# M3HN register map
File version: 0.1
Registers are 32-bit, read-write, reset 0x0 unless marked. A register's access mark holds for its fields unless they carry their own. Offsets are from the block's base; [hi:lo] are bit positions; {n}, {i} and the like mark numbered series.

## OFD
Base 0x400F1000
0x00 CR1 reset 0x6 — OFD Control Register 1
  [7:0] OFDWEN
0x04 CR2 — OFD Control Register 2
  [7:0] OFDEN
0x08 MN0 — OFD Lower Detection Frequency Setting Register0
  [11:0] OFDMN0
0x0C MN1 — OFD Lower Detection Frequency Setting Register1
  [11:0] OFDMN1
0x10 MX0 — OFD Higher Detection Frequency Setting Register0
  [11:0] OFDMX0
0x14 MX1 — OFD Higher Detection Frequency Setting Register1
  [11:0] OFDMX1
0x18 RST reset 0x1 — OFD Reset Enable Control Register
  [0] OFDRSTEN
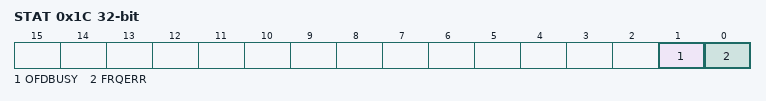
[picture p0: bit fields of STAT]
0x1C STAT ro — OFD Status Register
  [1] OFDBUSY, [0] FRQERR
0x20 MON reset 0x1 — OFD External high frequency oscillaion clock monitor register
  [0] OFDMON

## CG
Base 0x400F3000
0x00 PROTECT reset 0xC1 — CG Protect Register
  [7:0] PROTECT
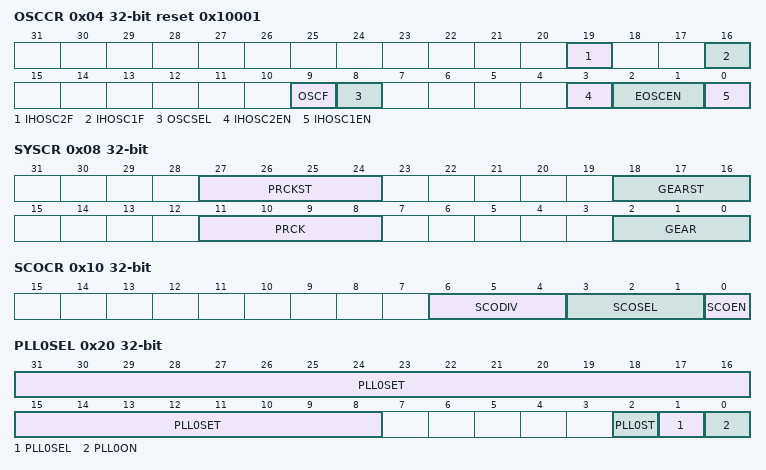
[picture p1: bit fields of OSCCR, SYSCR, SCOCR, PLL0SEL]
0x04 OSCCR reset 0x10001 — CG Oscillation Control Register
  [19] IHOSC2F ro, [16] IHOSC1F ro, [9] OSCF ro, [8] OSCSEL, [3] IHOSC2EN, [2:1] EOSCEN, [0] IHOSC1EN
0x08 SYSCR — CG System clock control register
  [27:24] PRCKST ro, [18:16] GEARST ro, [11:8] PRCK, [2:0] GEAR
0x0C STBYCR — CG Standby Control Register
  [1:0] STBY
0x10 SCOCR — CG SCOUT Control Register
  [6:4] SCODIV, [3:1] SCOSEL, [0] SCOEN
0x20 PLL0SEL — CG PLL select register for fsys
  [31:8] PLL0SET, [2] PLL0ST ro, [1] PLL0SEL, [0] PLL0ON
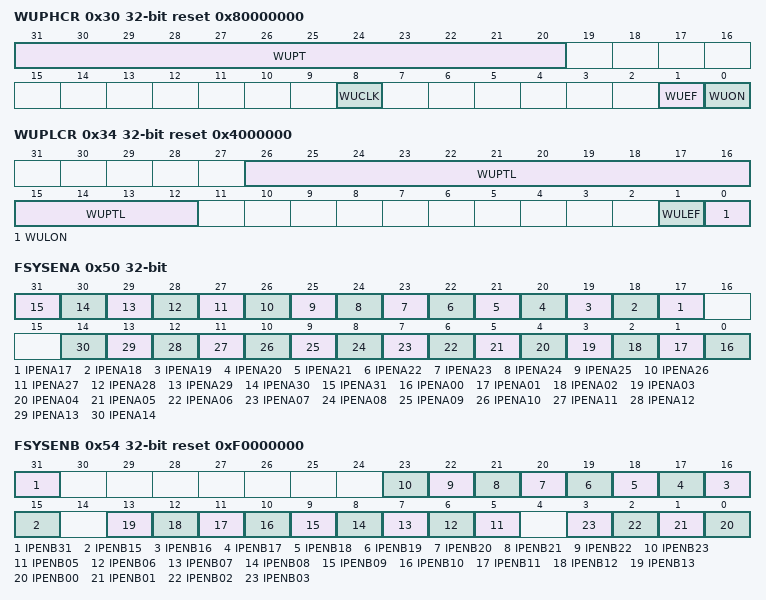
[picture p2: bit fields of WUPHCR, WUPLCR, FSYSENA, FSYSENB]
0x30 WUPHCR reset 0x80000000 — CG Warmup register for HOSC
  [31:20] WUPT, [8] WUCLK, [1] WUEF ro, [0] WUON wo
0x34 WUPLCR reset 0x4000000 — CG Low-speed oscillation warm-up register
  [26:12] WUPTL, [1] WULEF ro, [0] WULON wo
0x50 FSYSENA — CG output control register A for fsys clock
  [n] IPENA{n} (n=17..31), [n] IPENA{n:02} (n=0..14)
0x54 FSYSENB reset 0xF0000000 — CG output control register B for fsys clock
  [31] IPENB31, [n] IPENB{n} (n=15..23), [n] IPENB{n:02} (n=5..13), [n] IPENB{n:02} (n=0..3)
0x58 FCEN — CG output control register for fc clock
  [7] FCIPEN07
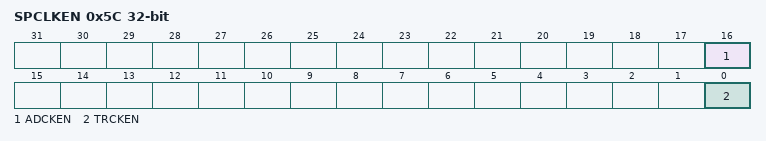
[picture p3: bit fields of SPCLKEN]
0x5C SPCLKEN — CG Output control register for ADC AND TRACE CLOCK
  [16] ADCKEN, [0] TRCKEN

## TRM
Base 0x400F3200
0x00 OSCPRO — TRM Protect register
  [7:0] PROTECT
0x04 OSCEN — TRM Enable register
  [0] TRIMEN
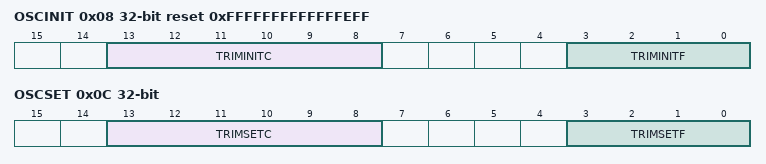
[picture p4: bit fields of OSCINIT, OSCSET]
0x08 OSCINIT ro reset 0xFFFFFFFFFFFFFEFF — TRM Initial trimming level monitor register
  [13:8] TRIMINITC, [3:0] TRIMINITF
0x0C OSCSET — TRM Trimming level setting register
  [13:8] TRIMSETC, [3:0] TRIMSETF

## IB — Interrupt control register B
Base 0x400F4E00
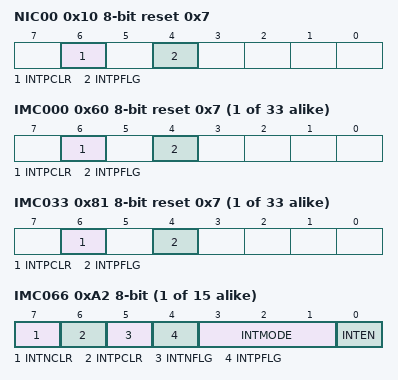
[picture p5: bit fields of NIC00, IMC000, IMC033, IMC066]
0x10 NIC00 8-bit reset 0x7 — Non makeable Interrupt Control(B) 00
  [6] INTPCLR wo, [4] INTPFLG ro
{0x60+i} IMC{i:03} 8-bit reset 0x7 (i=0..32) — Interrupu Mode Control Register(B) {i:03}
  [6] INTPCLR wo, [4] INTPFLG ro
{0x60+i} IMC{i:03} 8-bit reset 0x7 (i=33..65) — Interrupt Mode Control Register(B) {i:03}
  [6] INTPCLR wo, [4] INTPFLG ro
{0x60+i} IMC{i:03} 8-bit (i=66..80) — Interrupu Mode Control Register(B) {i:03}
  [7] INTNCLR wo, [6] INTPCLR wo, [5] INTNFLG ro, [4] INTPFLG ro, [3:1] INTMODE, [0] INTEN
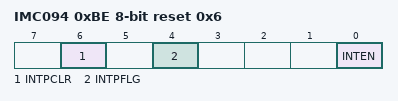
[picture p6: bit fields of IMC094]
0xBE IMC094 8-bit reset 0x6 — Interrupu Mode Control Register(B) 094
  [6] INTPCLR wo, [4] INTPFLG ro, [0] INTEN

## IMN
Base 0x400F4F00
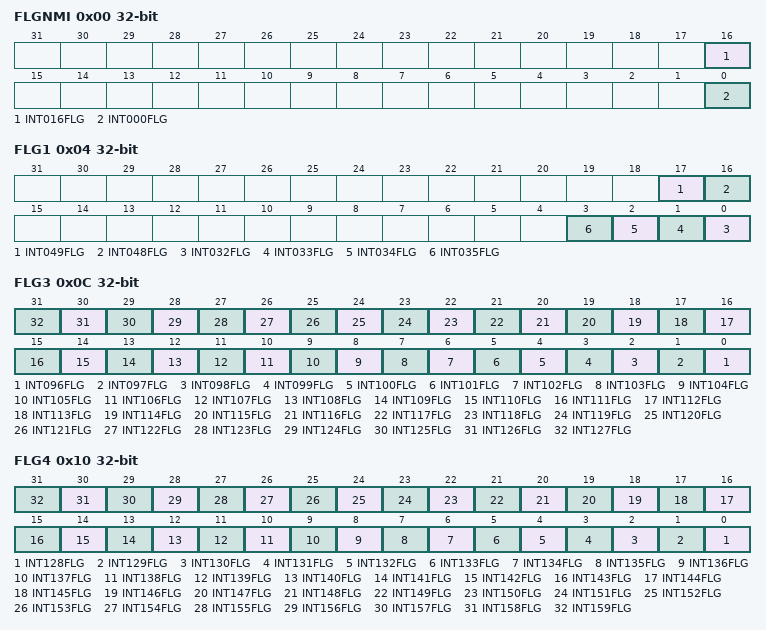
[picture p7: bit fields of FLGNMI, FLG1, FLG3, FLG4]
0x00 FLGNMI ro — Interrupt Monitor Flag 0
  [16] INT016FLG, [0] INT000FLG
0x04 FLG1 ro — Interrupt Monitor Flag 1
  [17] INT049FLG, [16] INT048FLG, [n-32] INT{n:03}FLG (n=32..35)
0x0C FLG3 ro — Interrupt Monitor Flag 3
  [n-96] INT{n:03}FLG (n=96..127)
0x10 FLG4 ro — NMI Interrupt Monitor Flag 4
  [n-128] INT{n}FLG (n=128..159)
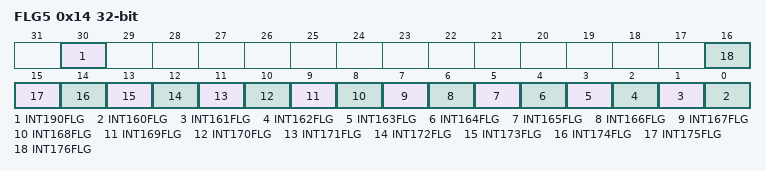
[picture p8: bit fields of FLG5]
0x14 FLG5 ro — NMI Interrupt Monitor Flag 5
  [30] INT190FLG, [n-160] INT{n}FLG (n=160..176)

## PMD
Base 0x400F6000
0x00 MDEN — PMD Enable Register
  [0] PWMEN
0x04 PORTMD — PMD Port Output Mode Register
  [1:0] PORTMD
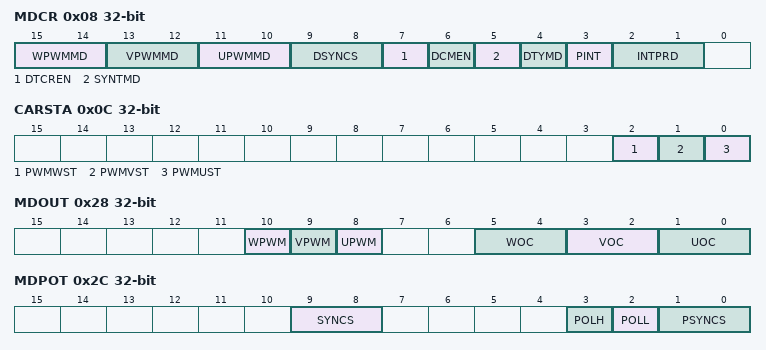
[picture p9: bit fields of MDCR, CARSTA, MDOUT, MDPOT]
0x08 MDCR — PMD Control Register
  [15:14] WPWMMD, [13:12] VPWMMD, [11:10] UPWMMD, [9:8] DSYNCS, [7] DTCREN, [6] DCMEN, [5] SYNTMD, [4] DTYMD, [3] PINT, [2:1] INTPRD
0x0C CARSTA ro — PWM Carrier Status Register
  [2] PWMWST, [1] PWMVST, [0] PWMUST
0x10 BCARI ro — PWM Basic Carrier Register
  [14:0] BCARI
0x14 RATE — PWM Frequency Register
  [14:0] RATE
0x18 CMPU — PMD PWM Compare U Register
  [15:0] CMPU
0x1C CMPV — PMD PWM Compare V Register
  [15:0] CMPV
0x20 CMPW — PMD PWM Compare W Register
  [15:0] CMPW
0x28 MDOUT — PMD Conduction Control Register
  [10] WPWM, [9] VPWM, [8] UPWM, [5:4] WOC, [3:2] VOC, [1:0] UOC
0x2C MDPOT — PMD Output Setting Register
  [9:8] SYNCS, [3] POLH, [2] POLL, [1:0] PSYNCS
0x30 EMGREL wo — PMD EMG Release Register
  [7:0] EMGREL
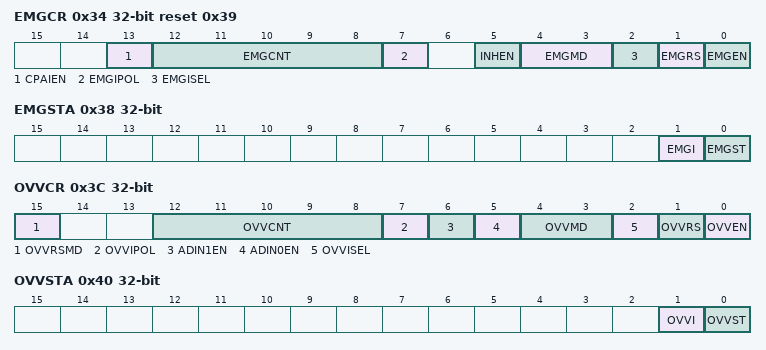
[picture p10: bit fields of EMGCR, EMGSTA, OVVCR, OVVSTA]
0x34 EMGCR reset 0x39 — PMD EMG Control Register
  [13] CPAIEN, [12:8] EMGCNT, [7] EMGIPOL, [5] INHEN, [4:3] EMGMD, [2] EMGISEL, [1] EMGRS wo, [0] EMGEN
0x38 EMGSTA ro (reset mask 0xFFFFFFFD) — PMD EMG Status Register
  [1] EMGI, [0] EMGST
0x3C OVVCR — PMD OVV Control Register
  [15] OVVRSMD, [12:8] OVVCNT, [7] OVVIPOL, [6] ADIN1EN, [5] ADIN0EN, [4:3] OVVMD, [2] OVVISEL, [1] OVVRS wo, [0] OVVEN
0x40 OVVSTA ro (reset mask 0xFFFFFFFD) — PMD OVV Status Register
  [1] OVVI, [0] OVVST
0x44 DTR — PMD Dead Time Register
  [9:0] DTR
{0x48+4i} TRGCMP{i} (i=0..3) — PMD Trigger Compare Register {i}
  [14:0] TRGCMP{i}
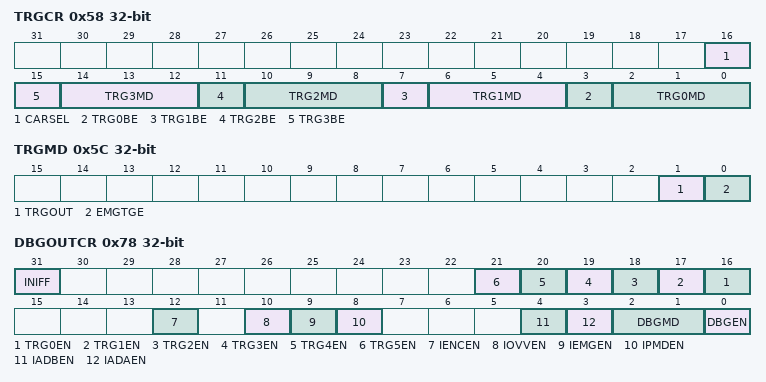
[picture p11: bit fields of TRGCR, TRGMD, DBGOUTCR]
0x58 TRGCR — PMD Trigger Control Register
  [16] CARSEL, [4n+3] TRG{n}BE (n=0..3), [4n+2:4n] TRG{n}MD (n=0..3)
0x5C TRGMD — PMD Trigger Output Mode Setting Register
  [1] TRGOUT, [0] EMGTGE
0x60 TRGSEL — PMD Trigger Output Select Register
  [2:0] TRGSEL
0x64 TRGSYNCR — PMD Trigger Update Timing Setting Register
  [1:0] TSYNCS
0x68 VPWMPH — Phase difference setting of the V-phase PWM
  [14:0] VPWMPH
0x6C WPWMPH — Phase difference setting of the W-phase PWM
  [14:0] WPWMPH
0x70 MBUFCR — Update timing of the triple buffer
  [2:0] BUFCTR
0x78 DBGOUTCR — Debug output control
  [31] INIFF, [n+16] TRG{n}EN (n=0..5), [12] IENCEN, [10] IOVVEN, [9] IEMGEN, [8] IPMDEN, [4] IADBEN, [3] IADAEN, [2:1] DBGMD, [0] DBGEN

## EN — Encoder Input (ENC)
Base 0x400F7000
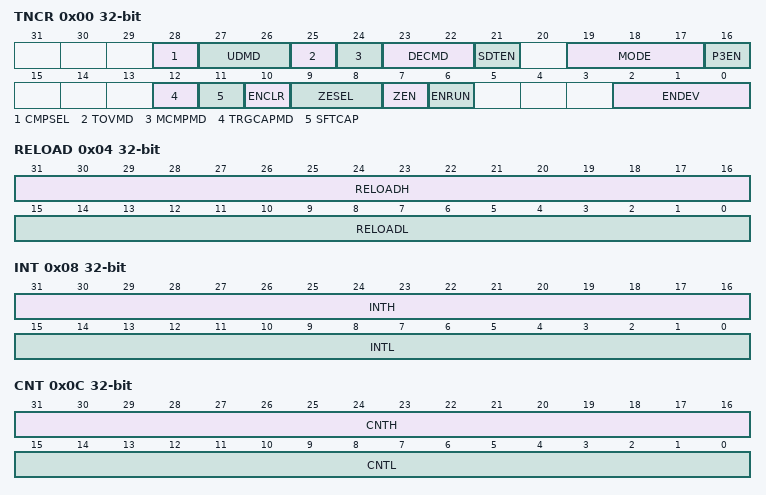
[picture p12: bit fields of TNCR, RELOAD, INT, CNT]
0x00 TNCR — ENC Control Register
  [28] CMPSEL, [27:26] UDMD, [25] TOVMD, [24] MCMPMD, [23:22] DECMD, [21] SDTEN, [19:17] MODE, [16] P3EN, [12] TRGCAPMD, [11] SFTCAP wo, [10] ENCLR wo, [9:8] ZESEL, [7] ZEN, [6] ENRUN, [2:0] ENDEV
0x04 RELOAD — ENC Reload Compare Register
  [31:16] RELOADH, [15:0] RELOADL
0x08 INT — ENC INT Compare Register
  [31:16] INTH, [15:0] INTL
0x0C CNT — ENC Counter_Capture Register
  [31:16] CNTH ro, [15:0] CNTL ro
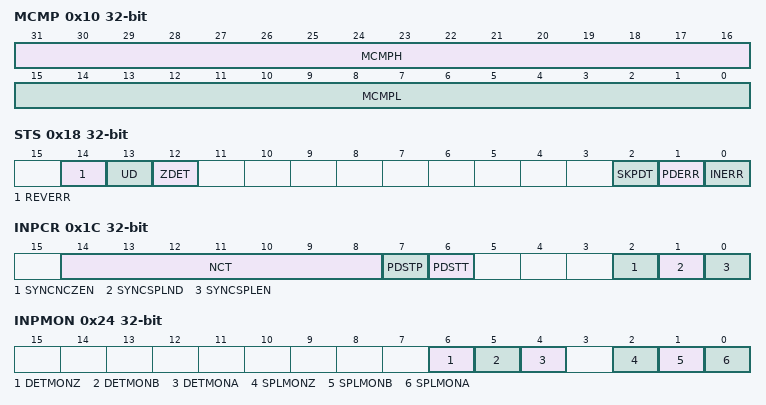
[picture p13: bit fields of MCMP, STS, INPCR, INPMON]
0x10 MCMP — ENC MCMP Compare Register
  [31:16] MCMPH, [15:0] MCMPL
0x14 RATE — ENC Phase Count Rate Register
  [15:0] RATE
0x18 STS ro — ENC Status Register
  [14] REVERR, [13] UD, [12] ZDET, [2] SKPDT, [1] PDERR, [0] INERR
0x1C INPCR — ENC Input Process Cntrol Register
  [14:8] NCT, [7] PDSTP wo, [6] PDSTT wo, [2] SYNCNCZEN, [1] SYNCSPLND, [0] SYNCSPLEN
0x20 SMPDLY — ENC Sample Delay Register
  [7:0] SMPDLY
0x24 INPMON ro — ENC Input Moniter Register
  [6] DETMONZ, [5] DETMONB, [4] DETMONA, [2] SPLMONZ, [1] SPLMONB, [0] SPLMONA
0x28 CLKCR — ENC Sample Clock Control Register
  [1:0] SPLCKS
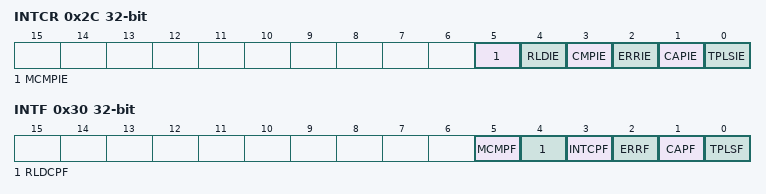
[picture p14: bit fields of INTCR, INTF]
0x2C INTCR — ENC Interrupt Reqyest Control Register
  [5] MCMPIE, [4] RLDIE, [3] CMPIE, [2] ERRIE, [1] CAPIE, [0] TPLSIE
0x30 INTF ro — ENC Interrupt Event Flag Register
  [5] MCMPF, [4] RLDCPF, [3] INTCPF, [2] ERRF, [1] CAPF, [0] TPLSF

## FC
Base 0x5DFF0000
0x10 SBMR reset 0x1 — Flash Security Bit Mask Register
  [0] SMB
0x14 SSR reset 0xFFFFFFFFFFFFFFFF — Flash Security Status Register
  [0] SEC ro
0x18 KCR wo — Flash Key Code Register
  [31:0] KEYCODE
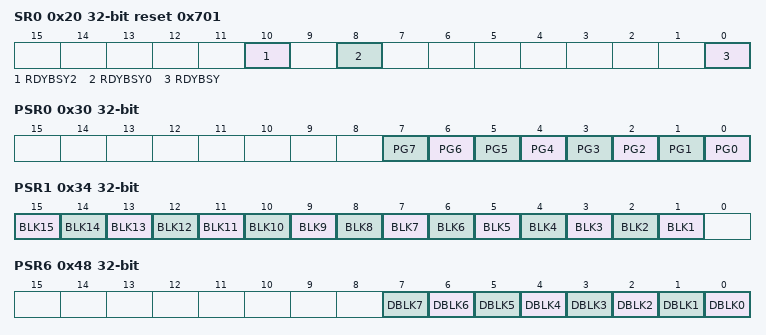
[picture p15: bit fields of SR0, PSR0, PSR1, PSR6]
0x20 SR0 reset 0x701 — Flash Status Register 0
  [10] RDYBSY2 ro, [8] RDYBSY0 ro, [0] RDYBSY ro
0x30 PSR0 ro (reset mask 0xFFFFFF00) — Flash Protect Status Register 0
  [n] PG{n} (n=0..7)
0x34 PSR1 ro (reset mask 0xFFFF0001) — Flash Protect Status Register 1
  [n] BLK{n} (n=1..15)
0x48 PSR6 ro (reset mask 0xFFFFFF00) — Flash Protect Status Register 6
  [n] DBLK{n} (n=0..7)
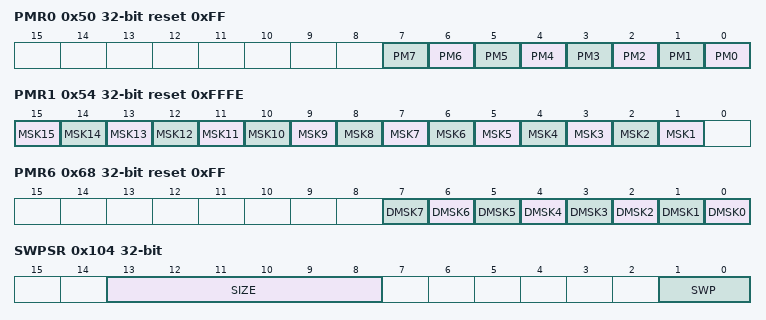
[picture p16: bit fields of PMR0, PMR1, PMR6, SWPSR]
0x50 PMR0 reset 0xFF — Flash Protect Mask Register 0
  [n] PM{n} (n=0..7)
0x54 PMR1 reset 0xFFFE — Flash Protect Mask Register 1
  [n] MSK{n} (n=1..15)
0x68 PMR6 reset 0xFF — Flash Protect Mask Register 6
  [n] DMSK{n} (n=0..7)
0x100 SR1 ro — Flash Status Register 1
  [24] WEABORT
0x104 SWPSR ro — Flash Memory SWP Status Register
  [13:8] SIZE, [1:0] SWP
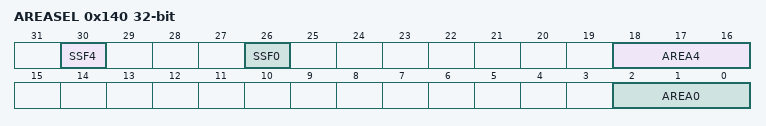
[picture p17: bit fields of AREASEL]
0x140 AREASEL — Flash Area Selection Register
  [30] SSF4 ro, [26] SSF0 ro, [18:16] AREA4, [2:0] AREA0
0x148 CR — Flash Control Register
  [2:0] WEABORT
0x14C STSCLR — Flash Status Clear Register
  [2:0] WEABORT
0x150 BNKCR — Flash Bank Change Register
  [2:0] BANK0
0x158 BUFDISCLR — Flash Buffer Disable and Clear Register
  [2:0] BUFDISCLR
